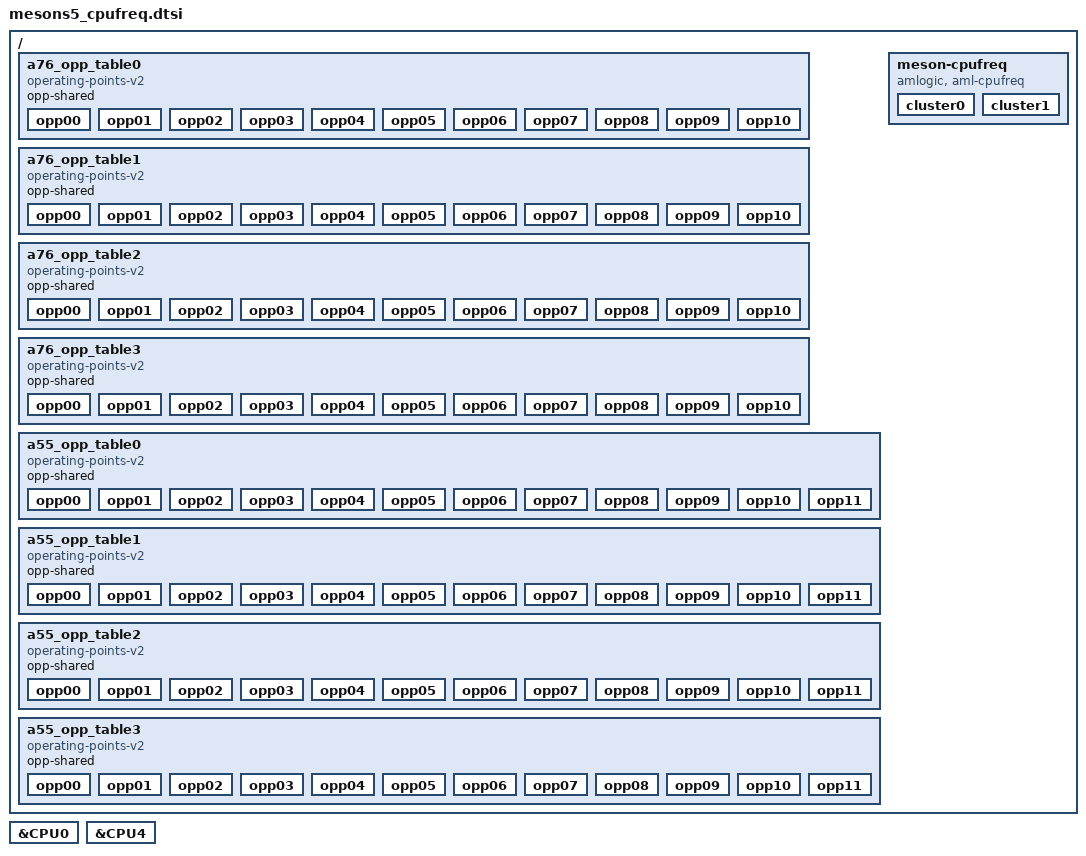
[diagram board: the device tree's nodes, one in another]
// SPDX-License-Identifier: (GPL-2.0+ OR MIT)
/*
 * Copyright (c) 2019 Amlogic, Inc. All rights reserved.
 */

/ {
	a76_opp_table0: a76_opp_table0 {
		compatible = "operating-points-v2";
		opp-shared;

		opp00 {
			opp-hz = /bits/ 64 <100000000>;
			opp-microvolt = <799000>;
		};
		opp01 {
			opp-hz = /bits/ 64 <500000000>;
			opp-microvolt = <799000>;
		};
		opp02 {
			opp-hz = /bits/ 64 <666000000>;
			opp-microvolt = <799000>;
		};
		opp03 {
			opp-hz = /bits/ 64 <1000000000>;
			opp-microvolt = <799000>;
		};
		opp04 {
			opp-hz = /bits/ 64 <1200000000>;
			opp-microvolt = <839000>;
		};
		opp05 {
			opp-hz = /bits/ 64 <1392000000>;
			opp-microvolt = <889000>;
		};
		opp06 {
			opp-hz = /bits/ 64 <1512000000>;
			opp-microvolt = <919000>;
		};
		opp07 {
			opp-hz = /bits/ 64 <1608000000>;
			opp-microvolt = <949000>;
		};
		opp08 {
			opp-hz = /bits/ 64 <1704000000>;
			opp-microvolt = <989000>;
		};
		opp09 {
			opp-hz = /bits/ 64 <1800000000>;
			opp-microvolt = <1009000>;
		};
		opp10 {
			opp-hz = /bits/ 64 <1896000000>;
			opp-microvolt = <1019000>;
		};
	};

	a76_opp_table1: a76_opp_table1 {
		compatible = "operating-points-v2";
		opp-shared;

		opp00 {
			opp-hz = /bits/ 64 <100000000>;
			opp-microvolt = <799000>;
		};
		opp01 {
			opp-hz = /bits/ 64 <500000000>;
			opp-microvolt = <799000>;
		};
		opp02 {
			opp-hz = /bits/ 64 <666000000>;
			opp-microvolt = <799000>;
		};
		opp03 {
			opp-hz = /bits/ 64 <1000000000>;
			opp-microvolt = <799000>;
		};
		opp04 {
			opp-hz = /bits/ 64 <1200000000>;
			opp-microvolt = <839000>;
		};
		opp05 {
			opp-hz = /bits/ 64 <1392000000>;
			opp-microvolt = <889000>;
		};
		opp06 {
			opp-hz = /bits/ 64 <1512000000>;
			opp-microvolt = <919000>;
		};
		opp07 {
			opp-hz = /bits/ 64 <1608000000>;
			opp-microvolt = <949000>;
		};
		opp08 {
			opp-hz = /bits/ 64 <1704000000>;
			opp-microvolt = <989000>;
		};
		opp09 {
			opp-hz = /bits/ 64 <1800000000>;
			opp-microvolt = <1009000>;
		};
		opp10 {
			opp-hz = /bits/ 64 <1896000000>;
			opp-microvolt = <1019000>;
		};
	};

	a76_opp_table2: a76_opp_table2 {
		compatible = "operating-points-v2";
		opp-shared;

		opp00 {
			opp-hz = /bits/ 64 <100000000>;
			opp-microvolt = <789000>;
		};
		opp01 {
			opp-hz = /bits/ 64 <500000000>;
			opp-microvolt = <789000>;
		};
		opp02 {
			opp-hz = /bits/ 64 <666000000>;
			opp-microvolt = <789000>;
		};
		opp03 {
			opp-hz = /bits/ 64 <1000000000>;
			opp-microvolt = <789000>;
		};
		opp04 {
			opp-hz = /bits/ 64 <1200000000>;
			opp-microvolt = <799000>;
		};
		opp05 {
			opp-hz = /bits/ 64 <1392000000>;
			opp-microvolt = <829000>;
		};
		opp06 {
			opp-hz = /bits/ 64 <1512000000>;
			opp-microvolt = <869000>;
		};
		opp07 {
			opp-hz = /bits/ 64 <1608000000>;
			opp-microvolt = <899000>;
		};
		opp08 {
			opp-hz = /bits/ 64 <1704000000>;
			opp-microvolt = <929000>;
		};
		opp09 {
			opp-hz = /bits/ 64 <1800000000>;
			opp-microvolt = <969000>;
		};
		opp10 {
			opp-hz = /bits/ 64 <1896000000>;
			opp-microvolt = <979000>;
		};
	};

	a76_opp_table3: a76_opp_table3 {
		compatible = "operating-points-v2";
		opp-shared;

		opp00 {
			opp-hz = /bits/ 64 <100000000>;
			opp-microvolt = <779000>;
		};
		opp01 {
			opp-hz = /bits/ 64 <500000000>;
			opp-microvolt = <779000>;
		};
		opp02 {
			opp-hz = /bits/ 64 <666000000>;
			opp-microvolt = <779000>;
		};
		opp03 {
			opp-hz = /bits/ 64 <1000000000>;
			opp-microvolt = <779000>;
		};
		opp04 {
			opp-hz = /bits/ 64 <1200000000>;
			opp-microvolt = <799000>;
		};
		opp05 {
			opp-hz = /bits/ 64 <1392000000>;
			opp-microvolt = <819000>;
		};
		opp06 {
			opp-hz = /bits/ 64 <1512000000>;
			opp-microvolt = <859000>;
		};
		opp07 {
			opp-hz = /bits/ 64 <1608000000>;
			opp-microvolt = <879000>;
		};
		opp08 {
			opp-hz = /bits/ 64 <1704000000>;
			opp-microvolt = <909000>;
		};
		opp09 {
			opp-hz = /bits/ 64 <1800000000>;
			opp-microvolt = <939000>;
		};
		opp10 {
			opp-hz = /bits/ 64 <1896000000>;
			opp-microvolt = <959000>;
		};
	};

	a55_opp_table0: a55_opp_table0 {
		compatible = "operating-points-v2";
		opp-shared;

		opp00 {
			opp-hz = /bits/ 64 <100000000>;
			opp-microvolt = <789000>;
		};
		opp01 {
			opp-hz = /bits/ 64 <500000000>;
			opp-microvolt = <789000>;
		};
		opp02 {
			opp-hz = /bits/ 64 <666000000>;
			opp-microvolt = <789000>;
		};
		opp03 {
			opp-hz = /bits/ 64 <1000000000>;
			opp-microvolt = <789000>;
		};
		opp04 {
			opp-hz = /bits/ 64 <1200000000>;
			opp-microvolt = <819000>;
		};
		opp05 {
			opp-hz = /bits/ 64 <1392000000>;
			opp-microvolt = <829000>;
		};
		opp06 {
			opp-hz = /bits/ 64 <1512000000>;
			opp-microvolt = <839000>;
		};
		opp07 {
			opp-hz = /bits/ 64 <1608000000>;
			opp-microvolt = <869000>;
		};
		opp08 {
			opp-hz = /bits/ 64 <1704000000>;
			opp-microvolt = <899000>;
		};
		opp09 {
			opp-hz = /bits/ 64 <1800000000>;
			opp-microvolt = <929000>;
		};
		opp10 {
			opp-hz = /bits/ 64 <1896000000>;
			opp-microvolt = <979000>;
		};
		opp11 {
			opp-hz = /bits/ 64 <2016000000>;
			opp-microvolt = <1009000>;
		};
	};

	a55_opp_table1: a55_opp_table1 {
		compatible = "operating-points-v2";
		opp-shared;

		opp00 {
			opp-hz = /bits/ 64 <100000000>;
			opp-microvolt = <789000>;
		};
		opp01 {
			opp-hz = /bits/ 64 <500000000>;
			opp-microvolt = <789000>;
		};
		opp02 {
			opp-hz = /bits/ 64 <666000000>;
			opp-microvolt = <789000>;
		};
		opp03 {
			opp-hz = /bits/ 64 <1000000000>;
			opp-microvolt = <789000>;
		};
		opp04 {
			opp-hz = /bits/ 64 <1200000000>;
			opp-microvolt = <819000>;
		};
		opp05 {
			opp-hz = /bits/ 64 <1392000000>;
			opp-microvolt = <829000>;
		};
		opp06 {
			opp-hz = /bits/ 64 <1512000000>;
			opp-microvolt = <839000>;
		};
		opp07 {
			opp-hz = /bits/ 64 <1608000000>;
			opp-microvolt = <869000>;
		};
		opp08 {
			opp-hz = /bits/ 64 <1704000000>;
			opp-microvolt = <899000>;
		};
		opp09 {
			opp-hz = /bits/ 64 <1800000000>;
			opp-microvolt = <929000>;
		};
		opp10 {
			opp-hz = /bits/ 64 <1896000000>;
			opp-microvolt = <979000>;
		};
		opp11 {
			opp-hz = /bits/ 64 <2016000000>;
			opp-microvolt = <1009000>;
		};
	};

	a55_opp_table2: a55_opp_table2 {
		compatible = "operating-points-v2";
		opp-shared;

		opp00 {
			opp-hz = /bits/ 64 <100000000>;
			opp-microvolt = <779000>;
		};
		opp01 {
			opp-hz = /bits/ 64 <500000000>;
			opp-microvolt = <779000>;
		};
		opp02 {
			opp-hz = /bits/ 64 <666000000>;
			opp-microvolt = <779000>;
		};
		opp03 {
			opp-hz = /bits/ 64 <1000000000>;
			opp-microvolt = <779000>;
		};
		opp04 {
			opp-hz = /bits/ 64 <1200000000>;
			opp-microvolt = <789000>;
		};
		opp05 {
			opp-hz = /bits/ 64 <1392000000>;
			opp-microvolt = <799000>;
		};
		opp06 {
			opp-hz = /bits/ 64 <1512000000>;
			opp-microvolt = <809000>;
		};
		opp07 {
			opp-hz = /bits/ 64 <1608000000>;
			opp-microvolt = <819000>;
		};
		opp08 {
			opp-hz = /bits/ 64 <1704000000>;
			opp-microvolt = <849000>;
		};
		opp09 {
			opp-hz = /bits/ 64 <1800000000>;
			opp-microvolt = <869000>;
		};
		opp10 {
			opp-hz = /bits/ 64 <1896000000>;
			opp-microvolt = <909000>;
		};
		opp11 {
			opp-hz = /bits/ 64 <2016000000>;
			opp-microvolt = <979000>;
		};
	};

	a55_opp_table3: a55_opp_table3 {
		compatible = "operating-points-v2";
		opp-shared;

		opp00 {
			opp-hz = /bits/ 64 <100000000>;
			opp-microvolt = <769000>;
		};
		opp01 {
			opp-hz = /bits/ 64 <500000000>;
			opp-microvolt = <769000>;
		};
		opp02 {
			opp-hz = /bits/ 64 <666000000>;
			opp-microvolt = <769000>;
		};
		opp03 {
			opp-hz = /bits/ 64 <1000000000>;
			opp-microvolt = <769000>;
		};
		opp04 {
			opp-hz = /bits/ 64 <1200000000>;
			opp-microvolt = <779000>;
		};
		opp05 {
			opp-hz = /bits/ 64 <1392000000>;
			opp-microvolt = <789000>;
		};
		opp06 {
			opp-hz = /bits/ 64 <1512000000>;
			opp-microvolt = <799000>;
		};
		opp07 {
			opp-hz = /bits/ 64 <1608000000>;
			opp-microvolt = <809000>;
		};
		opp08 {
			opp-hz = /bits/ 64 <1704000000>;
			opp-microvolt = <819000>;
		};
		opp09 {
			opp-hz = /bits/ 64 <1800000000>;
			opp-microvolt = <849000>;
		};
		opp10 {
			opp-hz = /bits/ 64 <1896000000>;
			opp-microvolt = <889000>;
		};
		opp11 {
			opp-hz = /bits/ 64 <2016000000>;
			opp-microvolt = <929000>;
		};
	};

	meson-cpufreq {
		compatible = "amlogic, aml-cpufreq";
		status = "okay";

		/*
		 * A55 and DSU share the same power and are provided by vddcpua
		 */
		cluster0-cpu-supply = <&vddcpua>;
		cluster1-cpu-supply = <&vddcpub>;
		cluster1-dsu-supply = <&vddcpua>;

		cluster0 {
			clocks = <&scmi_clk CLKID_CPU_CLK>,
				 <&scmi_clk CLKID_DSU_CLK>;
			clock-names = "cpuclk",
				      "dsuclk";
			voltage-tolerance = <0>;
			transition_delay_us = <10000>;
			cluster_cores = <0 1 2 3>;
			dsuclk_shared;
			pdvfs_enabled;
			/*
			 * cpu_clk–dsu_clk mapping relationship:
			 * 1. cpu_clk <= 1.2G:
			 *      - dsu_clk = cpu_clk;
			 * 2. 1.2G < cpu_clk <= 1.8G
			 *      - dsu_clk = 1.2G;
			 * 3. 1.8G < cpu_clk:
			 *      - dsu_clk = 1.5G;
			 */
			dsu-opp-table = <1200000 1200000>, /* follow CPU freq */
					<1896000 1500000>;
		};

		cluster1 {
			clocks = <&scmi_clk CLKID_A76_CLK>,
				 <&scmi_clk CLKID_DSU_CLK>;
			clock-names = "cpuclk",
				      "dsuclk";
			voltage-tolerance = <0>;
			transition_delay_us = <10000>;
			cluster_cores = <4>;
			dsuclk_shared;
			pdvfs_enabled;
			/*
			 * cpu_clk–dsu_clk–dsu_vol mapping relationship:
			 * 1. cpu_clk <= 1.2G:
			 *      - dsu_clk = cpu_clk; dsu_vol = cpu_vol;
			 * 2. 1.2G < cpu_clk <= 1.8G
			 *      - dsu_clk = 1.2G; dsu_vol = 0.879V;
			 * 3. 1.8G < cpu_clk:
			 *      - dsu_clk = 1.5G; dsu_vol = 0.939V;
			 */
					/* DSU freq and voltage follow CPU */
			dsu-opp-table0 = <1200000 1200000 839000>,
					/* DSU voltage for dsu_clk = 1.2G */
					 <1392000 1200000 879000>,
					/* DSU voltage for dsu_clk = 1.5G */
					 <1896000 1500000 939000>;
			dsu-opp-table1 = <1200000 1200000 839000>,
					 <1392000 1200000 879000>,
					 <1896000 1500000 939000>;
			dsu-opp-table2 = <1200000 1200000 799000>,
					 <1392000 1200000 879000>,
					 <1896000 1500000 939000>;
			dsu-opp-table3 = <1200000 1200000 799000>,
					 <1392000 1200000 879000>,
					 <1896000 1500000 939000>;
		};
	};
};/* end of / */

&CPU0 {
	operating-points-v2 = <&a55_opp_table0>,
			      <&a55_opp_table1>,
			      <&a55_opp_table2>,
			      <&a55_opp_table3>;
};

&CPU4 {
	operating-points-v2 = <&a76_opp_table0>,
			      <&a76_opp_table1>,
			      <&a76_opp_table2>,
			      <&a76_opp_table3>;
};
